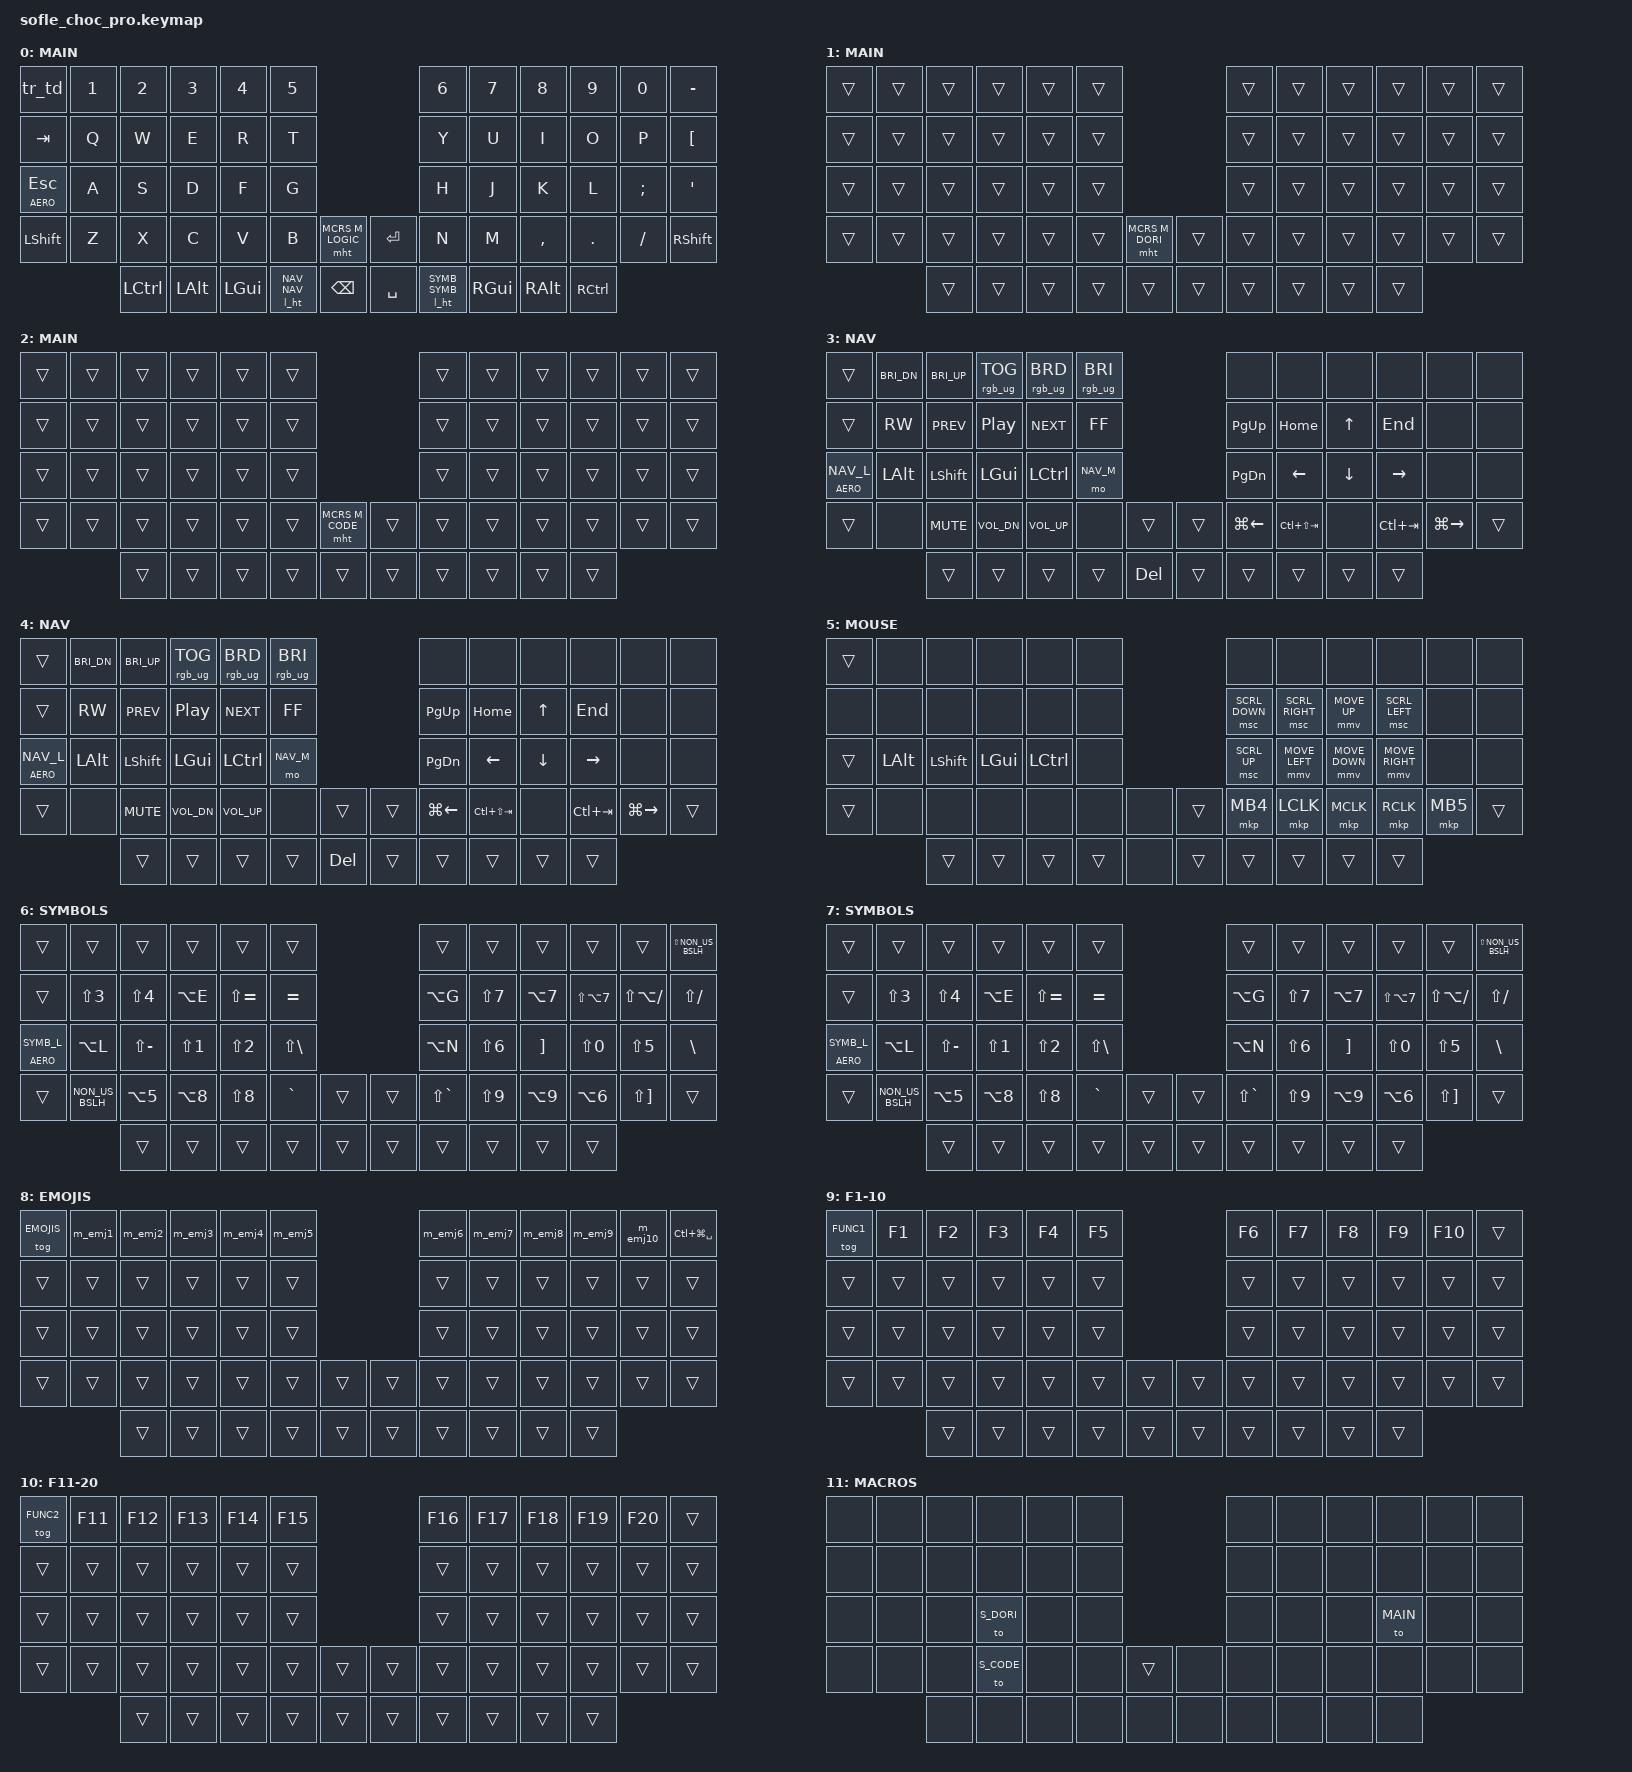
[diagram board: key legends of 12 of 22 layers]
/*
* Copyright (c) 2020 The ZMK Contributors
*
* SPDX-License-Identifier: MIT
*/

#include <behaviors.dtsi>
#include <dt-bindings/zmk/keys.h>
#include <dt-bindings/zmk/pointing.h>
#include <dt-bindings/zmk/bt.h>
#include <dt-bindings/zmk/rgb.h>
#include <dt-bindings/zmk/ext_power.h>

#define MAIN      0
#define S_DORI    1
#define S_CODE    2
#define NAV       3
#define NAV_L     4
#define NAV_M     5
#define SYMB      6
#define SYMB_L    7
#define EMOJIS    8
#define FUNC1     9
#define FUNC2     10
#define MCRS      11
#define M_LOGIC   12
#define M_LOGIC_L 13
#define M_DORI    14
#define M_DORI_L  15
#define M_CODE    16
#define M_CODE_L  17
#define AERO      18
#define AERO_L    19
#define AERO_R    20
#define SERV      21

#include "macros.dtsi"
#include "custom_behaviors.dtsi"

/ {
     // Activate SERVICE layer by pressing both NAV and SYMB
     conditional_layers {
          compatible = "zmk,conditional-layers";
          adjust_layer {
               if-layers = <NAV SYMB>;
               then-layer = <SERV>;
          };
     };

     keymap {
          compatible = "zmk,keymap";

          main_layer {
               display-name = "MAIN";
               bindings = <
               // ┌──────────────┬──────────────┬──────────────┬──────────────┬──────────────┬──────────────┐                              ┌──────────────┬──────────────┬──────────────┬──────────────┬──────────────┬──────────────┐
               // │ TR TAP DANCE │ 1            │ 2            │ 3            │ 4            │ 5            │                              │ 6            │ 7            │ 8            │ 9            │ 0            │ ß            │
                    &tr_td         &kp N1         &kp N2         &kp N3         &kp N4         &kp N5                                        &kp N6         &kp N7         &kp N8         &kp N9         &kp N0         &kp MINUS
               // ├──────────────┼──────────────┼──────────────┼──────────────┼──────────────┼──────────────┤                              ├──────────────┼──────────────┼──────────────┼──────────────┼──────────────┼──────────────┤
               // │ TAB          │ Q            │ W            │ E            │ R            │ T            │                              │ Z            │ U            │ I            │ O            │ P            │ Ü            │
                    &kp TAB        &kp Q          &kp W          &kp E          &kp R          &kp T                                         &kp Y          &kp U          &kp I          &kp O          &kp P          &kp LBKT
               // ├──────────────┼──────────────┼──────────────┼──────────────┼──────────────┼──────────────┤                              ├──────────────┼──────────────┼──────────────┼──────────────┼──────────────┼──────────────┤
               // │ ESC / AERO   │ A            │ S            │ D            │ F            │ G            │                              │ H            │ J            │ K            │ L            │ Ö            │ Ä            │
                    &as_t AERO ESC &kp A          &kp S          &kp D          &kp F          &kp G                                         &kp H          &kp J          &kp K          &kp L          &kp SEMI       &kp SQT
               // ├──────────────┼──────────────┼──────────────┼──────────────┼──────────────┼──────────────┼──────────────┐┌──────────────┼──────────────┼──────────────┼──────────────┼──────────────┼──────────────┼──────────────┤
               // │ SHIFT Left   │ Y            │ X            │ C            │ V            │ B            │ MACROS       ││ ENTER        │ N            │ M            │ ,            │ .            │ -            │ SHIFT Right  │
                    &kp LSHFT      &kp Z          &kp X          &kp C          &kp V          &kp B          &mht MCRS M_LOGIC &kp RET      &kp N          &kp M          &kp COMMA      &kp DOT        &kp FSLH       &kp RSHFT
               // └──────────────┴──────────────┼──────────────┼──────────────┼──────────────┼──────────────┼──────────────┤├──────────────┼──────────────┼──────────────┼──────────────┼──────────────┼──────────────┴──────────────┘
               //                               │ CTRL Left    │ OPT Left     │ CMD Left     │ NAV          │ BACKSPACE    ││ SPACE        │ SYMBOLS      │ CMD Right    │ OPT Right    │ CTRL Right   │
                                                  &kp LCTRL      &kp LALT       &kp LGUI       &l_ht NAV NAV  &kp BSPC        &kp SPACE      &l_ht SYMB SYMB  &kp RGUI     &kp RALT       &kp RCTRL
               //                               └──────────────┴──────────────┴──────────────┴──────────────┴──────────────┘└──────────────┴──────────────┴──────────────┴──────────────┴──────────────┘
               >;
          };

          macro_overlay_dorico_layer {
               display-name = "MAIN";
               bindings = <
                  &trans &trans &trans &trans &trans &trans                         &trans &trans &trans &trans &trans &trans
                  &trans &trans &trans &trans &trans &trans                         &trans &trans &trans &trans &trans &trans
                  &trans &trans &trans &trans &trans &trans                         &trans &trans &trans &trans &trans &trans
                  &trans &trans &trans &trans &trans &trans &mht MCRS M_DORI &trans &trans &trans &trans &trans &trans &trans
                                &trans &trans &trans &trans &trans           &trans &trans &trans &trans &trans
               >;
          };

          macro_overlay_coding_layer {
               display-name = "MAIN";
               bindings = <
                  &trans &trans &trans &trans &trans &trans                         &trans &trans &trans &trans &trans &trans
                  &trans &trans &trans &trans &trans &trans                         &trans &trans &trans &trans &trans &trans
                  &trans &trans &trans &trans &trans &trans                         &trans &trans &trans &trans &trans &trans
                  &trans &trans &trans &trans &trans &trans &mht MCRS M_CODE &trans &trans &trans &trans &trans &trans &trans
                                &trans &trans &trans &trans &trans           &trans &trans &trans &trans &trans
               >;
          };

          nav_layer {
               display-name = "NAV";
               bindings = <
               // ┌──────────────┬──────────────┬──────────────┬──────────────┬──────────────┬──────────────┐                              ┌──────────────┬──────────────┬──────────────┬──────────────┬──────────────┬──────────────┐
               // │              │ BRIGHTN DOWN │ BRIGHTN UP   │KB LI TOGGLE    KB LI DOWN   │ KB LI UP     │                              │              │              │              │              │              │              │
                    &trans         &kp C_BRI_DN   &kp C_BRI_UP  &rgb_ug RGB_TOG &rgb_ug RGB_BRD &rgb_ug RGB_BRI                              &none          &none          &none          &none          &none          &none
               // ├──────────────┼──────────────┼──────────────┼──────────────┼──────────────┼──────────────┤                              ├──────────────┼──────────────┼──────────────┼──────────────┼──────────────┼──────────────┤
               // │              │ REWIND       │ PREVIOUS     │ PLAY/PAUSE   │ NEXT         │ FAST FWD     │                              │ Page Up      │ Home         │ ↑            │ End          │              │              │
                    &trans         &kp C_RW       &kp C_PREV     &kp C_PP       &kp C_NEXT     &kp C_FF                                      &kp PG_UP      &kp HOME       &kp UP         &kp END        &none          &none
               // ├──────────────┼──────────────┼──────────────┼──────────────┼──────────────┼──────────────┤                              ├──────────────┼──────────────┼──────────────┼──────────────┼──────────────┼──────────────┤
               // │ LOCK/AERO    │ OPT Left     │ SHIFT Left   │ CMD Left     │ CTRL Left    │ MOUSE CTRL   │                              │ Page Down    │ ←            │ ↓            │ →            │              │              │
                    &as_l AERO NAV_L &kp LALT     &kp LSHFT      &kp LGUI       &kp LCTRL      &mo NAV_M                                     &kp PG_DN      &kp LEFT       &kp DOWN       &kp RIGHT      &none          &none
               // ├──────────────┼──────────────┼──────────────┼──────────────┼──────────────┼──────────────┼──────────────┐┌──────────────┼──────────────┼──────────────┼──────────────┼──────────────┼──────────────┼──────────────┤
               // │              │              │ MUTE         │ VOL DOWN     │ VOL UP       │              │              ││              │ Prev         │ Prev Tab     │              │ Next Tab     │ Next         │              │
                    &trans         &none          &kp C_MUTE     &kp C_VOL_DN   &kp C_VOL_UP   &none          &trans          &trans         &kp LG(LEFT)   &kp LC(LS(TAB)) &none         &kp LC(TAB)    &kp LG(RIGHT)  &trans
               // └──────────────┴──────────────┼──────────────┼──────────────┼──────────────┼──────────────┼──────────────┤├──────────────┼──────────────┼──────────────┼──────────────┼──────────────┼──────────────┴──────────────┘
               //                               │              │              │              │ (HELD)       │ DELETE       ││              │              │              │              │              │
                                                  &trans         &trans         &trans         &trans         &kp DEL         &trans         &trans         &trans         &trans         &trans
               //                               └──────────────┴──────────────┴──────────────┴──────────────┴──────────────┘└──────────────┴──────────────┴──────────────┴──────────────┴──────────────┘
               >;
          };

          nav_locked_layer {
               display-name = "NAV";
               bindings = <
               // ┌──────────────┬──────────────┬──────────────┬──────────────┬──────────────┬──────────────┐                              ┌──────────────┬──────────────┬──────────────┬──────────────┬──────────────┬──────────────┐
               // │              │ BRIGHTN DOWN │ BRIGHTN UP   │KB LI TOGGLE    KB LI DOWN   │ KB LI UP     │                              │              │              │              │              │              │              │
                    &trans         &kp C_BRI_DN   &kp C_BRI_UP  &rgb_ug RGB_TOG &rgb_ug RGB_BRD &rgb_ug RGB_BRI                              &none          &none          &none          &none          &none          &none
               // ├──────────────┼──────────────┼──────────────┼──────────────┼──────────────┼──────────────┤                              ├──────────────┼──────────────┼──────────────┼──────────────┼──────────────┼──────────────┤
               // │              │ REWIND       │ PREVIOUS     │ PLAY/PAUSE   │ NEXT         │ FAST FWD     │                              │ Page Up      │ Home         │ ↑            │ End          │              │              │
                    &trans         &kp C_RW       &kp C_PREV     &kp C_PP       &kp C_NEXT     &kp C_FF                                      &kp PG_UP      &kp HOME       &kp UP         &kp END        &none          &none
               // ├──────────────┼──────────────┼──────────────┼──────────────┼──────────────┼──────────────┤                              ├──────────────┼──────────────┼──────────────┼──────────────┼──────────────┼──────────────┤
               // │ UNLOCK/AERO  │ OPT Left     │ SHIFT Left   │ CMD Left     │ CTRL Left    │ MOUSE CTRL   │                              │ Page Down    │ ←            │ ↓            │ →            │              │              │
                    &as_l AERO NAV_L &kp LALT     &kp LSHFT      &kp LGUI       &kp LCTRL      &mo NAV_M                                     &kp PG_DN      &kp LEFT       &kp DOWN       &kp RIGHT      &none          &none
               // ├──────────────┼──────────────┼──────────────┼──────────────┼──────────────┼──────────────┼──────────────┐┌──────────────┼──────────────┼──────────────┼──────────────┼──────────────┼──────────────┼──────────────┤
               // │              │              │ MUTE         │ VOL DOWN     │ VOL UP       │              │              ││              │ Prev         │ Prev Tab     │              │ Next Tab     │ Next         │              │
                    &trans         &none          &kp C_MUTE     &kp C_VOL_DN   &kp C_VOL_UP   &none          &trans          &trans         &kp LG(LEFT)   &kp LC(LS(TAB)) &none         &kp LC(TAB)    &kp LG(RIGHT)  &trans
               // └──────────────┴──────────────┼──────────────┼──────────────┼──────────────┼──────────────┼──────────────┤├──────────────┼──────────────┼──────────────┼──────────────┼──────────────┼──────────────┴──────────────┘
               //                               │              │              │              │ (HELD)       │ DELETE       ││              │              │              │              │              │
                                                  &trans         &trans         &trans         &trans         &kp DEL         &trans         &trans         &trans         &trans         &trans
               //                               └──────────────┴──────────────┴──────────────┴──────────────┴──────────────┘└──────────────┴──────────────┴──────────────┴──────────────┴──────────────┘
               >;
          };

          nav_mouse_layer {
               display-name = "MOUSE";
               bindings = <
               // ┌──────────────┬──────────────┬──────────────┬──────────────┬──────────────┬──────────────┐                              ┌──────────────┬──────────────┬──────────────┬──────────────┬──────────────┬──────────────┐
               // │              │              │              │              │              │              │                              │              │              │              │              │              │              │
                    &trans         &none          &none          &none          &none          &none                                         &none          &none          &none          &none          &none          &none
               // ├──────────────┼──────────────┼──────────────┼──────────────┼──────────────┼──────────────┤                              ├──────────────┼──────────────┼──────────────┼──────────────┼──────────────┼──────────────┤
               // │              │              │              │              │              │              │                              │ ↑ SCROLL     │ ← SCROLL     │ ↑ MOVE       │ → SCROLL     │              │              │
                    &none          &none          &none          &none          &none          &none                                         &msc SCRL_DOWN &msc SCRL_RIGHT &mmv MOVE_UP   &msc SCRL_LEFT       &none   &none
               // ├──────────────┼──────────────┼──────────────┼──────────────┼──────────────┼──────────────┤                              ├──────────────┼──────────────┼──────────────┼──────────────┼──────────────┼──────────────┤
               // │              │ OPT Left     │ SHIFT Left   │ CMD Left     │ CTRL Left    │ (HELD)       │                              │ ↓ SCROLL     │ ← MOVE       │ ↓ MOVE       │ → MOVE       │              │              │
                    &trans         &kp LALT       &kp LSHFT      &kp LGUI       &kp LCTRL      &none                                         &msc SCRL_UP   &mmv MOVE_LEFT &mmv MOVE_DOWN &mmv MOVE_RIGHT       &none   &none
               // ├──────────────┼──────────────┼──────────────┼──────────────┼──────────────┼──────────────┼──────────────┐┌──────────────┼──────────────┼──────────────┼──────────────┼──────────────┼──────────────┼──────────────┤
               // │              │              │              │              │              │              │              ││              │ MB4 (BACK)   │ LEFT CLICK   │ MIDDLE CLICK │ RIGHT CLICK  │ MB5 (FWD)    │              │
                    &trans         &none          &none          &none          &none          &none          &none           &trans         &mkp MB4       &mkp LCLK      &mkp MCLK      &mkp RCLK      &mkp MB5       &trans
               // └──────────────┴──────────────┼──────────────┼──────────────┼──────────────┼──────────────┼──────────────┤├──────────────┼──────────────┼──────────────┼──────────────┼──────────────┼──────────────┴──────────────┘
               //                               │              │              │              │ (HELD)       │              ││              │              │              │              │              │
                                                  &trans         &trans         &trans         &trans         &none           &trans         &trans         &trans         &trans         &trans
               //                               └──────────────┴──────────────┴──────────────┴──────────────┴──────────────┘└──────────────┴──────────────┴──────────────┴──────────────┴──────────────┘
               >;
          };

          symbol_layer {
               display-name = "SYMBOLS";
               bindings = <
               // ┌──────────────┬──────────────┬──────────────┬──────────────┬──────────────┬──────────────┐                              ┌──────────────┬──────────────┬──────────────┬──────────────┬──────────────┬──────────────┐
               // │              │              │              │              │              │              │                              │              │              │              │              │              │ °            │
                    &trans         &trans         &trans         &trans         &trans         &trans                                        &trans         &trans         &trans         &trans         &trans         &kp LS(NON_US_BSLH)
               // ├──────────────┼──────────────┼──────────────┼──────────────┼──────────────┼──────────────┤                              ├──────────────┼──────────────┼──────────────┼──────────────┼──────────────┼──────────────┤
               // │              │ §            │ $            │ €            │ `            │ ´            │                              │ ©            │ /            │ |            │ \            │ —            │ _            │
                    &trans         &kp LS(N3)     &kp LS(N4)     &kp LA(E)      &kp LS(EQUAL)  &kp EQUAL                                     &kp LA(G)      &kp LS(N7)     &kp LA(N7)     &kp LS(LA(N7)) &kp LS(LA(FSLH)) &kp LS(FSLH)
               // ├──────────────┼──────────────┼──────────────┼──────────────┼──────────────┼──────────────┤                              ├──────────────┼──────────────┼──────────────┼──────────────┼──────────────┼──────────────┤
               // │ LOCK/AERO    │ @            │ ?            │ !            │ "            │ '            │                              │ ~            │ &            │ +            │ =            │ %            │ #            │
                    &as_l AERO SYMB_L &kp LA(L)   &kp LS(MINUS)  &kp LS(N1)     &kp LS(N2)     &kp LS(BSLH)                                  &kp LA(N)      &kp LS(N6)     &kp RBKT       &kp LS(N0)     &kp LS(N5)     &kp BSLH
               // ├──────────────┼──────────────┼──────────────┼──────────────┼──────────────┼──────────────┼──────────────┐┌──────────────┼──────────────┼──────────────┼──────────────┼──────────────┼──────────────┼──────────────┤
               // │              │ ^            │ [            │ {            │ (            │ <            │              ││              │ >            │ )            │ }            │ ]            │ *            │              │
                    &trans         &kp NON_US_BSLH &kp LA(N5)    &kp LA(N8)     &kp LS(N8)     &kp GRAVE      &trans          &trans         &kp LS(GRAVE)   &kp LS(N9)     &kp LA(N9)     &kp LA(N6)     &kp LS(RBKT)   &trans
               // └──────────────┴──────────────┼──────────────┼──────────────┼──────────────┼──────────────┼──────────────┤├──────────────┼──────────────┼──────────────┼──────────────┼──────────────┼──────────────┴──────────────┘
               //                               │              │              │              │              │              ││              │ (HELD)       │              │              │              │
                                                  &trans         &trans         &trans         &trans         &trans          &trans         &trans         &trans         &trans         &trans
               //                               └──────────────┴──────────────┴──────────────┴──────────────┴──────────────┘└──────────────┴──────────────┴──────────────┴──────────────┴──────────────┘
               >;
          };

          symbol_locked_layer {
               display-name = "SYMBOLS";
               bindings = <
               // ┌──────────────┬──────────────┬──────────────┬──────────────┬──────────────┬──────────────┐                              ┌──────────────┬──────────────┬──────────────┬──────────────┬──────────────┬──────────────┐
               // │              │              │              │              │              │              │                              │              │              │              │              │              │ °            │
                    &trans         &trans         &trans         &trans         &trans         &trans                                        &trans         &trans         &trans         &trans         &trans         &kp LS(NON_US_BSLH)
               // ├──────────────┼──────────────┼──────────────┼──────────────┼──────────────┼──────────────┤                              ├──────────────┼──────────────┼──────────────┼──────────────┼──────────────┼──────────────┤
               // │              │ §            │ $            │ €            │ `            │ ´            │                              │ ©            │ /            │ |            │ \            │ —            │ _            │
                    &trans         &kp LS(N3)     &kp LS(N4)     &kp LA(E)      &kp LS(EQUAL)  &kp EQUAL                                     &kp LA(G)      &kp LS(N7)     &kp LA(N7)     &kp LS(LA(N7)) &kp LS(LA(FSLH)) &kp LS(FSLH)
               // ├──────────────┼──────────────┼──────────────┼──────────────┼──────────────┼──────────────┤                              ├──────────────┼──────────────┼──────────────┼──────────────┼──────────────┼──────────────┤
               // │ UNLOCK/AERO  │ @            │ ?            │ !            │ "            │ '            │                              │ ~            │ &            │ +            │ =            │ %            │ #            │
                    &as_l AERO SYMB_L &kp LA(L)   &kp LS(MINUS)  &kp LS(N1)     &kp LS(N2)     &kp LS(BSLH)                                  &kp LA(N)      &kp LS(N6)     &kp RBKT       &kp LS(N0)     &kp LS(N5)     &kp BSLH
               // ├──────────────┼──────────────┼──────────────┼──────────────┼──────────────┼──────────────┼──────────────┐┌──────────────┼──────────────┼──────────────┼──────────────┼──────────────┼──────────────┼──────────────┤
               // │              │ ^            │ [            │ {            │ (            │ <            │              ││              │ >            │ )            │ }            │ ]            │ *            │              │
                    &trans         &kp NON_US_BSLH &kp LA(N5)    &kp LA(N8)     &kp LS(N8)     &kp GRAVE      &trans          &trans         &kp LS(GRAVE)   &kp LS(N9)     &kp LA(N9)     &kp LA(N6)     &kp LS(RBKT)   &trans
               // └──────────────┴──────────────┼──────────────┼──────────────┼──────────────┼──────────────┼──────────────┤├──────────────┼──────────────┼──────────────┼──────────────┼──────────────┼──────────────┴──────────────┘
               //                               │              │              │              │              │              ││              │ (HELD)       │              │              │              │
                                                  &trans         &trans         &trans         &trans         &trans          &trans         &trans         &trans         &trans         &trans
               //                               └──────────────┴──────────────┴──────────────┴──────────────┴──────────────┘└──────────────┴──────────────┴──────────────┴──────────────┴──────────────┘
               >;
          };

          emoji_layer {
               display-name = "EMOJIS";
               bindings = <
               // ┌──────────────┬──────────────┬──────────────┬──────────────┬──────────────┬──────────────┐                              ┌──────────────┬──────────────┬──────────────┬──────────────┬──────────────┬──────────────┐
               // │ Exit Emojis  │ 😊           │ 🤗            │ 😂           │ 😅           │ 🥲            │                              │ ❤️           │ 😍           │ 👍🏻            │ 🙈           │ 🤔           │ More Emojis  │
                    &tog EMOJIS    &m_emj1        &m_emj2        &m_emj3        &m_emj4        &m_emj5                                       &m_emj6        &m_emj7        &m_emj8        &m_emj9        &m_emj10       &kp LC(LG(SPACE))
               // ├──────────────┼──────────────┼──────────────┼──────────────┼──────────────┼──────────────┤                              ├──────────────┼──────────────┼──────────────┼──────────────┼──────────────┼──────────────┤
                    &trans         &trans         &trans         &trans         &trans         &trans                                        &trans         &trans         &trans         &trans         &trans         &trans
                    &trans         &trans         &trans         &trans         &trans         &trans                                        &trans         &trans         &trans         &trans         &trans         &trans
                    &trans         &trans         &trans         &trans         &trans         &trans         &trans          &trans         &trans         &trans         &trans         &trans         &trans         &trans
                                                  &trans         &trans         &trans         &trans         &trans          &trans         &trans         &trans         &trans         &trans
               >;
          };

          function1_layer {
               display-name = "F1-10";
               bindings = <
               // ┌──────────────┬──────────────┬──────────────┬──────────────┬──────────────┬──────────────┐                              ┌──────────────┬──────────────┬──────────────┬──────────────┬──────────────┬──────────────┐
               // │ Exit FUNC1   │ F1           │ F2           │ F3           │ F4           │ F5           │                              │ F6           │ F7           │ F8           │ F9           │ F10          │              │
                    &tog FUNC1     &kp F1         &kp F2         &kp F3         &kp F4         &kp F5                                        &kp F6         &kp F7         &kp F8         &kp F9         &kp F10        &trans
               // ├──────────────┼──────────────┼──────────────┼──────────────┼──────────────┼──────────────┤                              ├──────────────┼──────────────┼──────────────┼──────────────┼──────────────┼──────────────┤
                    &trans         &trans         &trans         &trans         &trans         &trans                                        &trans         &trans         &trans         &trans         &trans         &trans
                    &trans         &trans         &trans         &trans         &trans         &trans                                        &trans         &trans         &trans         &trans         &trans         &trans
                    &trans         &trans         &trans         &trans         &trans         &trans         &trans          &trans         &trans         &trans         &trans         &trans         &trans         &trans
                                                  &trans         &trans         &trans         &trans         &trans          &trans         &trans         &trans         &trans         &trans
               >;
          };

          function2_layer {
               display-name = "F11-20";
               bindings = <
               // ┌──────────────┬──────────────┬──────────────┬──────────────┬──────────────┬──────────────┐                              ┌──────────────┬──────────────┬──────────────┬──────────────┬──────────────┬──────────────┐
               // │ Exit FUNC2   │ F11          │ F12          │ F13          │ F14          │ F15          │                              │ F16          │ F17          │ F18          │ F19          │ F20          │              │
                    &tog FUNC2     &kp F11        &kp F12        &kp F13        &kp F14        &kp F15                                       &kp F16        &kp F17        &kp F18        &kp F19        &kp F20        &trans
               // ├──────────────┼──────────────┼──────────────┼──────────────┼──────────────┼──────────────┤                              ├──────────────┼──────────────┼──────────────┼──────────────┼──────────────┼──────────────┤
                    &trans         &trans         &trans         &trans         &trans         &trans                                        &trans         &trans         &trans         &trans         &trans         &trans
                    &trans         &trans         &trans         &trans         &trans         &trans                                        &trans         &trans         &trans         &trans         &trans         &trans
                    &trans         &trans         &trans         &trans         &trans         &trans         &trans          &trans         &trans         &trans         &trans         &trans         &trans         &trans
                                                  &trans         &trans         &trans         &trans         &trans          &trans         &trans         &trans         &trans         &trans
               >;
          };

          macros_select_layer {
               display-name = "MACROS";
               bindings = <
               // ┌──────────────┬──────────────┬──────────────┬──────────────┬──────────────┬──────────────┐                              ┌──────────────┬──────────────┬──────────────┬──────────────┬──────────────┬──────────────┐
               // │              │              │              │              │              │              │                              │              │              │              │              │              │              │
                    &none          &none          &none          &none          &none          &none                                         &none          &none          &none          &none          &none          &none
               // ├──────────────┼──────────────┼──────────────┼──────────────┼──────────────┼──────────────┤                              ├──────────────┼──────────────┼──────────────┼──────────────┼──────────────┼──────────────┤
               // │              │              │              │              │              │              │                              │              │              │              │              │              │              │
                    &none          &none          &none          &none          &none          &none                                         &none          &none          &none          &none          &none          &none
               // ├──────────────┼──────────────┼──────────────┼──────────────┼──────────────┼──────────────┤                              ├──────────────┼──────────────┼──────────────┼──────────────┼──────────────┼──────────────┤
               // │              │              │              │ DORICO       │              │              │                              │              │              │              │ LOGIC        │              │              │
                    &none          &none          &none          &to S_DORI     &none          &none                                         &none          &none          &none          &to MAIN       &none          &none
               // ├──────────────┼──────────────┼──────────────┼──────────────┼──────────────┼──────────────┼──────────────┐┌──────────────┼──────────────┼──────────────┼──────────────┼──────────────┼──────────────┼──────────────┤
               // │              │              │              │ CODING       │              │              │ (Held)       ││              │              │              │              │              │              │              │
                    &none          &none          &none          &to S_CODE     &none          &none          &trans          &none          &none          &none          &none          &none          &none          &none
               // └──────────────┴──────────────┼──────────────┼──────────────┼──────────────┼──────────────┼──────────────┤├──────────────┼──────────────┼──────────────┼──────────────┼──────────────┼──────────────┴──────────────┘
               //                               │              │              │              │              │              ││              │              │              │              │              │
                                                  &none          &none          &none          &none          &none           &none          &none          &none          &none          &none
               //                               └──────────────┴──────────────┴──────────────┴──────────────┴──────────────┘└──────────────┴──────────────┴──────────────┴──────────────┴──────────────┘
               >;
          };

          macros_logic_layer {
               display-name = "LOGIC";
               bindings = <
               // ┌──────────────┬──────────────┬──────────────┬──────────────┬──────────────┬──────────────┐                              ┌──────────────┬──────────────┬──────────────┬──────────────┬──────────────┬──────────────┐
               // │              │              │              │              │              │              │                              │              │              │              │              │              │              │
                    &none          &none          &none          &none          &none          &none                                         &none          &none          &none          &none          &none          &none
               // ├──────────────┼──────────────┼──────────────┼──────────────┼──────────────┼──────────────┤                              ├──────────────┼──────────────┼──────────────┼──────────────┼──────────────┼──────────────┤
               // │              │              │ MOVE ←       │ MOVE →       │ MV->REC-POS  │ MV->PLAYHEAD │                              │              │ JUMP REGION ←│              │ JUMP REGION →│              │              │
                    &none          &none          &kp LA(LEFT)   &kp LA(RIGHT)  &kp LS(LA(LG(R))) &kp LG(BSLH)                               &none          &kp LS(LA(LG(LEFT)))  &none   &kp LS(LA(LG(RIGHT))) &none   &none
               // ├──────────────┼──────────────┼──────────────┼──────────────┼──────────────┼──────────────┤                              ├──────────────┼──────────────┼──────────────┼──────────────┼──────────────┼──────────────┤
               // │ LOCK/AERO    │ POINTER      │ SCISSORS     │ PENCIL/DRAW  │ FADE         │ GAIN         │                              │              │ SET IN-PT    │ SET IN-OUT   │ SET OUT-PT   │              │              │
                    &as_l AERO M_LOGIC_L &kp LS(LA(LG(P))) &kp LS(LA(LG(S))) &kp LS(LA(LG(LBKT))) &kp LS(LA(LG(F))) &kp LS(LA(LG(G)))        &none          &kp LC(LG(X))  &kp LG(U)      &kp LS(LA(LC(L)))     &none   &none
               // ├──────────────┼──────────────┼──────────────┼──────────────┼──────────────┼──────────────┼──────────────┐┌──────────────┼──────────────┼──────────────┼──────────────┼──────────────┼──────────────┼──────────────┤
               // │              │              │              │              │              │              │              ││              │              │              │              │              │              │              │
                    &none          &none          &none          &none          &none          &none          &none           &none          &none          &none          &none          &none          &none          &none
               // └──────────────┴──────────────┼──────────────┼──────────────┼──────────────┼──────────────┼──────────────┤├──────────────┼──────────────┼──────────────┼──────────────┼──────────────┼──────────────┴──────────────┘
               //                               │              │              │              │              │              ││              │              │              │              │              │
                                                  &none          &none          &none          &to MAIN       &none           &none          &to MAIN       &none          &none          &none
               //                               └──────────────┴──────────────┴──────────────┴──────────────┴──────────────┘└──────────────┴──────────────┴──────────────┴──────────────┴──────────────┘
               >;
          };

          macros_logic_locked_layer {
               display-name = "LOGIC";
               bindings = <
               // ┌──────────────┬──────────────┬──────────────┬──────────────┬──────────────┬──────────────┐                              ┌──────────────┬──────────────┬──────────────┬──────────────┬──────────────┬──────────────┐
               // │              │              │              │              │              │              │                              │              │              │              │              │              │              │
                    &none          &none          &none          &none          &none          &none                                         &none          &none          &none          &none          &none          &none
               // ├──────────────┼──────────────┼──────────────┼──────────────┼──────────────┼──────────────┤                              ├──────────────┼──────────────┼──────────────┼──────────────┼──────────────┼──────────────┤
               // │              │              │ MOVE ←       │ MOVE →       │ MV->REC-POS  │ MV->PLAYHEAD │                              │              │ JUMP REGION ←│              │ JUMP REGION →│              │              │
                    &none          &none          &kp LA(LEFT)   &kp LA(RIGHT)  &kp LS(LA(LG(R))) &kp LG(BSLH)                               &none          &kp LS(LA(LG(LEFT)))  &none   &kp LS(LA(LG(RIGHT))) &none   &none
               // ├──────────────┼──────────────┼──────────────┼──────────────┼──────────────┼──────────────┤                              ├──────────────┼──────────────┼──────────────┼──────────────┼──────────────┼──────────────┤
               // │ UNLOCK/AERO  │ POINTER      │ SCISSORS     │ PENCIL/DRAW  │ FADE         │ GAIN         │                              │              │ SET IN-PT    │ SET IN-OUT   │ SET OUT-PT   │              │              │
                    &as_l AERO M_LOGIC_L &kp LS(LA(LG(P))) &kp LS(LA(LG(S))) &kp LS(LA(LG(LBKT))) &kp LS(LA(LG(F))) &kp LS(LA(LG(G)))        &none          &kp LC(LG(X))  &kp LG(U)      &kp LS(LA(LC(L)))     &none   &none
               // ├──────────────┼──────────────┼──────────────┼──────────────┼──────────────┼──────────────┼──────────────┐┌──────────────┼──────────────┼──────────────┼──────────────┼──────────────┼──────────────┼──────────────┤
               // │              │              │              │              │              │              │              ││              │              │              │              │              │              │              │
                    &none          &none          &none          &none          &none          &none          &none           &none          &none          &none          &none          &none          &none          &none
               // └──────────────┴──────────────┼──────────────┼──────────────┼──────────────┼──────────────┼──────────────┤├──────────────┼──────────────┼──────────────┼──────────────┼──────────────┼──────────────┴──────────────┘
               //                               │              │              │              │              │              ││              │              │              │              │              │
                                                  &none          &none          &none          &to MAIN       &none           &none          &to MAIN       &none          &none          &none
               //                               └──────────────┴──────────────┴──────────────┴──────────────┴──────────────┘└──────────────┴──────────────┴──────────────┴──────────────┴──────────────┘
               >;
          };

          macros_dorico_layer {
               display-name = "DORICO";
               bindings = <
               // ┌──────────────┬──────────────┬──────────────┬──────────────┬──────────────┬──────────────┐                              ┌──────────────┬──────────────┬──────────────┬──────────────┬──────────────┬──────────────┐
               // │              │ Filt Select  │ Filt Desel.  │ Filt Lyrics  │ Filt Techni. │ Filt Dyn.    │                              │ Filt Top N.  │ Filt Bot N.  │ Filt Slurs   │ Filt Rests   │ Filt Tupl.   │ Filt Gliss.  │
                    &none          &kp LC(LA(S))  &kp LC(LA(LG(S))) &kp LC(LG(L)) &kp LC(LG(P)) &kp LS(LC(LG(D)))                            &kp LC(LG(UP)) &kp LC(LG(DOWN)) &kp LC(LG(S)) &kp LC(LG(R)) &kp LC(LG(N))  &kp LS(LA(LG(G)))
               // ├──────────────┼──────────────┼──────────────┼──────────────┼──────────────┼──────────────┤                              ├──────────────┼──────────────┼──────────────┼──────────────┼──────────────┼──────────────┤
               // │              │              │ Prev Layout  │ Next Layout  │ Rem Trem.    │ Add Tremolo  │                              │ Def. N.head  │ Decr Dyn Int │ Move/Cpy Up  │ Incr Dyn Int │ Page View    │ Res. Beaming │
                    &none          &none     &kp LC(LA(LG(UP))) &kp LC(LA(LG(DOWN))) &kp LS(LA(LG(T))) &kp LA(LG(T))                         &kp LC(LA(LG(X))) &kp LC(LA(LG(U))) &dori_up &kp LC(LA(LG(O))) &kp LA(LG(N1)) &kp LC(LA(B))
               // ├──────────────┼──────────────┼──────────────┼──────────────┼──────────────┼──────────────┤                              ├──────────────┼──────────────┼──────────────┼──────────────┼──────────────┼──────────────┤
               // │ LOCK/AERO    │ Align Dyn.   │ Unison       │ Divisi       │ Filt Notes   │              │                              │ X Notehead   │ Decr Grid    │ Move/Cpy Dwn │ Incr Grid    │ Galley View  │ Res. Stems   │
                    &as_l AERO M_DORI_L &kp LS(LA(LG(A))) &kp LS(LC(D)) &kp LS(LG(D)) &kp LC(LA(LG(N))) &none                                &kp LS(LA(LG(X))) &kp LC(LA(LG(LEFT))) &dori_dn &kp LC(LA(LG(RIGHT))) &kp LA(LG(N2)) &kp LS(LA(LG(S)))
               // ├──────────────┼──────────────┼──────────────┼──────────────┼──────────────┼──────────────┼──────────────┐┌──────────────┼──────────────┼──────────────┼──────────────┼──────────────┼──────────────┼──────────────┤
               // │ SHIFT LEFT   │ Rem.Dyn.f.G. │ Ungroup Dyn. │ Group Dyn.   │ Filt&Rm Dyn. │ Dbl. Barline │              ││              │              │              │ Select More  │              │              │              │
                    &kp LSHFT      &kp LC(LG(G))  &kp LC(LA(LG(G))) &kp LC(LA(G)) &m_d_frd     &m_d_dbar      &none           &none          &none          &none          &kp LS(LG(A))  &none          &none          &none
               // └──────────────┴──────────────┼──────────────┼──────────────┼──────────────┼──────────────┼──────────────┤├──────────────┼──────────────┼──────────────┼──────────────┼──────────────┼──────────────┴──────────────┘
               //                               │              │              │              │              │              ││              │              │              │              │              │
                                                  &none          &none          &none          &to S_DORI     &none           &none          &to S_DORI     &none          &none          &none
               //                               └──────────────┴──────────────┴──────────────┴──────────────┴──────────────┘└──────────────┴──────────────┴──────────────┴──────────────┴──────────────┘
               >;
          };

          macros_dorico_locked_layer {
               display-name = "DORICO";
               bindings = <
               // ┌──────────────┬──────────────┬──────────────┬──────────────┬──────────────┬──────────────┐                              ┌──────────────┬──────────────┬──────────────┬──────────────┬──────────────┬──────────────┐
               // │              │ Filt Select  │ Filt Desel.  │ Filt Lyrics  │ Filt Techni. │ Filt Dyn.    │                              │ Filt Top N.  │ Filt Bot N.  │ Filt Slurs   │ Filt Rests   │ Filt Tupl.   │ Filt Gliss.  │
                    &none          &kp LC(LA(S))  &kp LC(LA(LG(S))) &kp LC(LG(L)) &kp LC(LG(P)) &kp LS(LC(LG(D)))                            &kp LC(LG(UP)) &kp LC(LG(DOWN)) &kp LC(LG(S)) &kp LC(LG(R)) &kp LC(LG(N))  &kp LS(LA(LG(G)))
               // ├──────────────┼──────────────┼──────────────┼──────────────┼──────────────┼──────────────┤                              ├──────────────┼──────────────┼──────────────┼──────────────┼──────────────┼──────────────┤
               // │              │              │ Prev Layout  │ Next Layout  │ Rem Trem.    │ Add Tremolo  │                              │ Def. N.head  │ Decr Dyn Int │ Move/Cpy Up  │ Incr Dyn Int │ Page View    │ Res. Beaming │
                    &none          &none     &kp LC(LA(LG(UP))) &kp LC(LA(LG(DOWN))) &kp LS(LA(LG(T))) &kp LA(LG(T))                         &kp LC(LA(LG(X))) &kp LC(LA(LG(U))) &dori_up &kp LC(LA(LG(O))) &kp LA(LG(N1)) &kp LC(LA(B))
               // ├──────────────┼──────────────┼──────────────┼──────────────┼──────────────┼──────────────┤                              ├──────────────┼──────────────┼──────────────┼──────────────┼──────────────┼──────────────┤
               // │ UNLOCK/AERO  │ Align Dyn.   │ Unison       │ Divisi       │ Filt Notes   │              │                              │ X Notehead   │ Decr Grid    │ Move/Cpy Dwn │ Incr Grid    │ Galley View  │ Res. Stems   │
                    &as_l AERO M_DORI_L &kp LS(LA(LG(A))) &kp LS(LC(D)) &kp LS(LG(D)) &kp LC(LA(LG(N))) &none                                &kp LS(LA(LG(X))) &kp LC(LA(LG(LEFT))) &dori_dn &kp LC(LA(LG(RIGHT))) &kp LA(LG(N2)) &kp LS(LA(LG(S)))
               // ├──────────────┼──────────────┼──────────────┼──────────────┼──────────────┼──────────────┼──────────────┐┌──────────────┼──────────────┼──────────────┼──────────────┼──────────────┼──────────────┼──────────────┤
               // │ SHIFT LEFT   │ Rem.Dyn.f.G. │ Ungroup Dyn. │ Group Dyn.   │ Filt&Rm Dyn. │ Dbl. Barline │              ││              │              │              │ Select More  │              │              │              │
                    &kp LSHFT      &kp LC(LG(G))  &kp LC(LA(LG(G))) &kp LC(LA(G)) &m_d_frd     &m_d_dbar      &none           &none          &none          &none          &kp LS(LG(A))  &none          &none          &none
               // └──────────────┴──────────────┼──────────────┼──────────────┼──────────────┼──────────────┼──────────────┤├──────────────┼──────────────┼──────────────┼──────────────┼──────────────┼──────────────┴──────────────┘
               //                               │              │              │              │              │              ││              │              │              │              │              │
                                                  &none          &none          &none          &to S_DORI     &none           &none          &to S_DORI     &none          &none          &none
               //                               └──────────────┴──────────────┴──────────────┴──────────────┴──────────────┘└──────────────┴──────────────┴──────────────┴──────────────┴──────────────┘
               >;
          };

          macros_coding_layer {
               display-name = "CODING";
               bindings = <
               // ┌──────────────┬──────────────┬──────────────┬──────────────┬──────────────┬──────────────┐                              ┌──────────────┬──────────────┬──────────────┬──────────────┬──────────────┬──────────────┐
               // │              │              │              │              │              │              │                              │              │              │              │              │              │              │
                    &none          &none          &none          &none          &none          &none                                         &none          &none          &none          &none          &none          &none
               // ├──────────────┼──────────────┼──────────────┼──────────────┼──────────────┼──────────────┤                              ├──────────────┼──────────────┼──────────────┼──────────────┼──────────────┼──────────────┤
               // │              │              │              │              │              │ VSC Terminal │                              │ <?php        │ /**          │ /* */        │ var_dump     │ console.log  │              │
                    &none          &none          &none          &none          &none          &kp LG(J)                                     &m_c_php       &m_c_docb      &m_c_bcom      &m_c_vdmp      &m_c_clog      &none
               // ├──────────────┼──────────────┼──────────────┼──────────────┼──────────────┼──────────────┤                              ├──────────────┼──────────────┼──────────────┼──────────────┼──────────────┼──────────────┤
               // │ LOCK/AERO    │ (() => {})   │              │              │ VSC Format   │ VSC Search   │                              │ $this->      │ ->           │ =>           │ ===          │ !==          │              │
                    &as_l AERO M_CODE_L &m_c_afnc &none          &none          &kp LS(LA(F))  &kp LS(LG(F))                                 &m_c_this      &m_c_tarr      &m_c_farr      &m_c_seq       &m_c_sneq      &none
               // ├──────────────┼──────────────┼──────────────┼──────────────┼──────────────┼──────────────┼──────────────┐┌──────────────┼──────────────┼──────────────┼──────────────┼──────────────┼──────────────┼──────────────┤
               // │              │              │              │              │              │              │              ││              │ <?=          │ END + ;      │ END + ; + RET│ !important   │              │              │
                    &none          &none          &none          &none          &none          &none          &none           &none          &m_c_php_e     &m_c_end       &m_c_endn      &m_c_imp       &none          &none
               // └──────────────┴──────────────┼──────────────┼──────────────┼──────────────┼──────────────┼──────────────┤├──────────────┼──────────────┼──────────────┼──────────────┼──────────────┼──────────────┴──────────────┘
               //                               │              │              │              │              │              ││              │              │              │              │              │
                                                  &none          &none          &none          &to S_CODE     &none           &none          &to S_CODE     &none          &none          &none
               //                               └──────────────┴──────────────┴──────────────┴──────────────┴──────────────┘└──────────────┴──────────────┴──────────────┴──────────────┴──────────────┘
               >;
          };

          macros_coding_locked_layer {
               display-name = "CODING";
               bindings = <
               // ┌──────────────┬──────────────┬──────────────┬──────────────┬──────────────┬──────────────┐                              ┌──────────────┬──────────────┬──────────────┬──────────────┬──────────────┬──────────────┐
               // │              │              │              │              │              │              │                              │              │              │              │              │              │              │
                    &none          &none          &none          &none          &none          &none                                         &none          &none          &none          &none          &none          &none
               // ├──────────────┼──────────────┼──────────────┼──────────────┼──────────────┼──────────────┤                              ├──────────────┼──────────────┼──────────────┼──────────────┼──────────────┼──────────────┤
               // │              │              │              │              │              │ VSC Terminal │                              │ <?php        │ /**          │ /* */        │ var_dump     │ console.log  │              │
                    &none          &none          &none          &none          &none          &kp LG(J)                                     &m_c_php       &m_c_docb      &m_c_bcom      &m_c_vdmp      &m_c_clog      &none
               // ├──────────────┼──────────────┼──────────────┼──────────────┼──────────────┼──────────────┤                              ├──────────────┼──────────────┼──────────────┼──────────────┼──────────────┼──────────────┤
               // │ LOCK/AERO    │ (() => {})   │              │              │ VSC Format   │ VSC Search   │                              │ $this->      │ ->           │ =>           │ ===          │ !==          │              │
                    &as_l AERO M_CODE_L &m_c_afnc &none          &none          &kp LS(LA(F))  &kp LS(LG(F))                                 &m_c_this      &m_c_tarr      &m_c_farr      &m_c_seq       &m_c_sneq      &none
               // ├──────────────┼──────────────┼──────────────┼──────────────┼──────────────┼──────────────┼──────────────┐┌──────────────┼──────────────┼──────────────┼──────────────┼──────────────┼──────────────┼──────────────┤
               // │              │              │              │              │              │              │              ││              │ <?=          │ END + ;      │ END + ; + RET│ !important   │              │              │
                    &none          &none          &none          &none          &none          &none          &none           &none          &m_c_php_e     &m_c_end       &m_c_endn      &m_c_imp       &none          &none
               // └──────────────┴──────────────┼──────────────┼──────────────┼──────────────┼──────────────┼──────────────┤├──────────────┼──────────────┼──────────────┼──────────────┼──────────────┼──────────────┴──────────────┘
               //                               │              │              │              │              │              ││              │              │              │              │              │
                                                  &none          &none          &none          &to S_CODE     &none           &none          &to S_CODE     &none          &none          &none
               //                               └──────────────┴──────────────┴──────────────┴──────────────┴──────────────┘└──────────────┴──────────────┴──────────────┴──────────────┴──────────────┘
               >;
          };

          aero_layer {
               display-name = "AERO";
               bindings = <
               // ┌──────────────┬──────────────┬──────────────┬──────────────┬──────────────┬──────────────┐                              ┌──────────────┬──────────────┬──────────────┬──────────────┬──────────────┬──────────────┐
               // │              │ Workspace 1  │ Workspace 2  │ Workspace 3  │ Workspace 4  │ Workspace 5  │                              │ Workspace 6  │ Workspace 7  │ Workspace 8  │ Workspace 9  │ Workspace 10 │              │
                    &trans         &kp LA(LC(N1)) &kp LA(LC(N2)) &kp LA(LC(N3)) &kp LA(LC(N4)) &kp LA(LC(N5))                                &kp LA(LC(N6)) &kp LA(LC(N7)) &kp LA(LC(N8)) &kp LA(LC(N9)) &kp LA(LC(N0)) &none
               // ├──────────────┼──────────────┼──────────────┼──────────────┼──────────────┼──────────────┤                              ├──────────────┼──────────────┼──────────────┼──────────────┼──────────────┼──────────────┤
               // │ TOGGLE WSPACE│ TOGGLE WSPACE│ PREV WSPACE  │ NEXT WSPACE  │ AERO RESIZE  │              │                              │              │ SHIFT LEFT   │ ↑            │              │              │              │
                    &kp LA(LC(TAB)) &kp LA(LC(TAB)) &kp LA(LC(W)) &kp LA(LC(E)) &mo AERO_R     &none                                         &none          &kp LSHFT      &kp LA(LC(UP)) &none          &none          &none
               // ├──────────────┼──────────────┼──────────────┼──────────────┼──────────────┼──────────────┤                              ├──────────────┼──────────────┼──────────────┼──────────────┼──────────────┼──────────────┤
               // │ (HELD)       │ LOCK         │ SHIFT LEFT   │ CMD LEFT     │ FULLSCREEN   │              │                              │ CMD LEFT     │ ←            │ ↓            │ →            │ Menu         │              │
                    &trans         &tog AERO_L    &kp LSHFT      &kp LGUI       &kp LA(LC(F))  &none                                         &kp LGUI     &kp LA(LC(LEFT)) &kp LA(LC(DOWN)) &kp LA(LC(RIGHT)) &kp LA(LC(SEMI))    &none
               // ├──────────────┼──────────────┼──────────────┼──────────────┼──────────────┼──────────────┼──────────────┐┌──────────────┼──────────────┼──────────────┼──────────────┼──────────────┼──────────────┼──────────────┤
               // │              │              │              │              │ FLOATING/TILING             │              ││              │ Workspace 1  │ Workspace 2  │ Workspace 3  │ Workspace 4  │ Workspace 5  │              │
                    &none          &none          &none          &none          &kp LS(LA(LC(F)))     &none   &none           &none          &kp LA(LC(N1)) &kp LA(LC(N2)) &kp LA(LC(N3)) &kp LA(LC(N4)) &kp LA(LC(N5)) &none
               // └──────────────┴──────────────┼──────────────┼──────────────┼──────────────┼──────────────┼──────────────┤├──────────────┼──────────────┼──────────────┼──────────────┼──────────────┼──────────────┴──────────────┘
               //                               │              │              │              │              │ LAUNCH MODE  ││ ALFRED       │              │              │              │              │
                                                  &none          &none          &none          &none   &kp LS(LA(LC(SPACE)))  &kp LA(LC(SPACE))     &none   &none          &none          &none
               //                               └──────────────┴──────────────┴──────────────┴──────────────┴──────────────┘└──────────────┴──────────────┴──────────────┴──────────────┴──────────────┘
               >;
          };

          aero_locked_layer {
               display-name = "AERO";
               bindings = <
               // ┌──────────────┬──────────────┬──────────────┬──────────────┬──────────────┬──────────────┐                              ┌──────────────┬──────────────┬──────────────┬──────────────┬──────────────┬──────────────┐
               // │              │ Workspace 1  │ Workspace 2  │ Workspace 3  │ Workspace 4  │ Workspace 5  │                              │ Workspace 6  │ Workspace 7  │ Workspace 8  │ Workspace 9  │ Workspace 10 │              │
                    &trans         &kp LA(LC(N1)) &kp LA(LC(N2)) &kp LA(LC(N3)) &kp LA(LC(N4)) &kp LA(LC(N5))                                &kp LA(LC(N6)) &kp LA(LC(N7)) &kp LA(LC(N8)) &kp LA(LC(N9)) &kp LA(LC(N0)) &none
               // ├──────────────┼──────────────┼──────────────┼──────────────┼──────────────┼──────────────┤                              ├──────────────┼──────────────┼──────────────┼──────────────┼──────────────┼──────────────┤
               // │ TOGGLE WSPACE│ TOGGLE WSPACE│ PREV WSPACE  │ NEXT WSPACE  │ AERO RESIZE  │              │                              │              │ SHIFT LEFT   │ ↑            │              │              │              │
                    &kp LA(LC(TAB)) &kp LA(LC(TAB)) &kp LA(LC(W)) &kp LA(LC(E)) &mo AERO_R     &none                                         &none          &kp LSHFT      &kp LA(LC(UP)) &none          &none          &none
               // ├──────────────┼──────────────┼──────────────┼──────────────┼──────────────┼──────────────┤                              ├──────────────┼──────────────┼──────────────┼──────────────┼──────────────┼──────────────┤
               // │ UNLOCK       │ UNLOCK       │ SHIFT LEFT   │ CMD LEFT     │ FULLSCREEN   │              │                              │ CMD LEFT     │ ←            │ ↓            │ →            │ Menu         │              │
                    &tog AERO_L    &tog AERO_L    &kp LSHFT      &kp LGUI       &kp LA(LC(F))  &none                                         &kp LGUI     &kp LA(LC(LEFT)) &kp LA(LC(DOWN)) &kp LA(LC(RIGHT)) &kp LA(LC(SEMI))    &none
               // ├──────────────┼──────────────┼──────────────┼──────────────┼──────────────┼──────────────┼──────────────┐┌──────────────┼──────────────┼──────────────┼──────────────┼──────────────┼──────────────┼──────────────┤
               // │              │              │              │              │ FLOATING/TILING             │              ││              │ Workspace 1  │ Workspace 2  │ Workspace 3  │ Workspace 4  │ Workspace 5  │              │
                    &none          &none          &none          &none          &kp LS(LA(LC(F)))     &none   &none           &none          &kp LA(LC(N1)) &kp LA(LC(N2)) &kp LA(LC(N3)) &kp LA(LC(N4)) &kp LA(LC(N5)) &none
               // └──────────────┴──────────────┼──────────────┼──────────────┼──────────────┼──────────────┼──────────────┤├──────────────┼──────────────┼──────────────┼──────────────┼──────────────┼──────────────┴──────────────┘
               //                               │              │              │              │              │ LAUNCH MODE  ││ ALFRED       │              │              │              │              │
                                                  &none          &none          &none          &none   &kp LS(LA(LC(SPACE)))  &kp LA(LC(SPACE))     &none   &none          &none          &none
               //                               └──────────────┴──────────────┴──────────────┴──────────────┴──────────────┘└──────────────┴──────────────┴──────────────┴──────────────┴──────────────┘
               >;
          };

          aero_resize_layer {
               display-name = "RESIZE";
               bindings = <
               // ┌──────────────┬──────────────┬──────────────┬──────────────┬──────────────┬──────────────┐                              ┌──────────────┬──────────────┬──────────────┬──────────────┬──────────────┬──────────────┐
               // │              │              │              │              │              │              │                              │              │              │              │              │              │              │
                    &trans         &none          &none          &none          &none          &none                                         &none          &none          &none          &none          &none          &none
               // ├──────────────┼──────────────┼──────────────┼──────────────┼──────────────┼──────────────┤                              ├──────────────┼──────────────┼──────────────┼──────────────┼──────────────┼──────────────┤
               // │              │              │              │ BIG RESIZE   │ (HELD)       │              │                              │                BALANCE SIZE │ ↑            │ FLATTEN TREE │              │              │
                    &none          &none          &none          &kp LSHFT      &trans         &none                                         &none        &kp LA(LC(F20))  &kp LA(LC(F18)) &kp LS(LA(LC(F20)))  &none   &none
               // ├──────────────┼──────────────┼──────────────┼──────────────┼──────────────┼──────────────┤                              ├──────────────┼──────────────┼──────────────┼──────────────┼──────────────┼──────────────┤
               // │ (HELD)       │              │              │              │              │              │                              │              │ ←            │ ↓            │ →            │              │              │
                    &trans         &none          &none          &none          &none          &none                                         &none        &kp LA(LC(F16)) &kp LA(LC(F19)) &kp LA(LC(F17))       &none   &none
               // ├──────────────┼──────────────┼──────────────┼──────────────┼──────────────┼──────────────┼──────────────┐┌──────────────┼──────────────┼──────────────┼──────────────┼──────────────┼──────────────┼──────────────┤
               // │              │              │              │              │              │              │              ││              │              │              │              │              │              │              │
                    &none          &none          &none          &none          &none          &none          &none           &none          &none          &none          &none          &none          &none          &none
               // └──────────────┴──────────────┼──────────────┼──────────────┼──────────────┼──────────────┼──────────────┤├──────────────┼──────────────┼──────────────┼──────────────┼──────────────┼──────────────┴──────────────┘
               //                               │              │              │              │              │              ││              │              │              │              │              │
                                                  &none          &none          &none          &none          &none           &none          &none          &none          &none          &none
               //                               └──────────────┴──────────────┴──────────────┴──────────────┴──────────────┘└──────────────┴──────────────┴──────────────┴──────────────┴──────────────┘
               >;
          };

          service_layer {
               display-name = "SERVICE";
               bindings = <
               // ┌──────────────┬──────────────┬──────────────┬──────────────┬──────────────┬──────────────┐                              ┌──────────────┬──────────────┬──────────────┬──────────────┬──────────────┬──────────────┐
               // │              │ BLUETOOTH 1  │ BLUETOOTH 2  │ BLUETOOTH 3  │ BLUETOOTH 4  │ BLUETOOTH 5  │                              │              │              │              │              │              │ BT CLEAR     │
                    &none          &bt BT_SEL 0   &bt BT_SEL 1   &bt BT_SEL 2   &bt BT_SEL 3   &bt BT_SEL 4                                  &none          &none          &none          &none          &none          &bt BT_CLR
               // ├──────────────┼──────────────┼──────────────┼──────────────┼──────────────┼──────────────┤                              ├──────────────┼──────────────┼──────────────┼──────────────┼──────────────┼──────────────┤
               // │              │              │              │              │              │              │                              │ RGB TOGGLE   │ BRI DOWN     │ BRI UP       │ ANIM PREV    │ ANIM NEXT    │              │
                    &none          &none          &none          &none          &none          &none                                        &rgb_ug RGB_TOG &rgb_ug RGB_BRD &rgb_ug RGB_BRI &rgb_ug RGB_EFR &rgb_ug RGB_EFF    &none
               // ├──────────────┼──────────────┼──────────────┼──────────────┼──────────────┼──────────────┤                              ├──────────────┼──────────────┼──────────────┼──────────────┼──────────────┼──────────────┤
               // │ (UN)LOCK     │              │              │              │              │              │                              │              │ HUE DOWN     │ HUE UP       │ SPEED DOWN   │ SPEED UP     │              │
                    &tog SERV      &none          &none          &none          &none          &none                                         &none         &rgb_ug RGB_HUD &rgb_ug RGB_HUI &rgb_ug RGB_SPD &rgb_ug RGB_SPI     &none
               // ├──────────────┼──────────────┼──────────────┼──────────────┼──────────────┼──────────────┼──────────────┐┌──────────────┼──────────────┼──────────────┼──────────────┼──────────────┼──────────────┼──────────────┤
               // │              │              │              │              │              │              │              ││ ZMK Studio Unlock           │ SAT DOWN     │ SAT UP       │              │              │              │
                    &none          &none          &none          &none          &none          &none          &none           &studio_unlock &none          &rgb_ug RGB_SAD &rgb_ug RGB_SAI &none        &none          &none
               // └──────────────┴──────────────┼──────────────┼──────────────┼──────────────┼──────────────┼──────────────┤├──────────────┼──────────────┼──────────────┼──────────────┼──────────────┼──────────────┴──────────────┘
               //                               │              │              │              │ (HELD)       │              ││              │ (HELD)       │              │              │              │
                                                  &none          &none          &none          &trans         &none           &none          &trans         &none          &none          &none
               //                               └──────────────┴──────────────┴──────────────┴──────────────┴──────────────┘└──────────────┴──────────────┴──────────────┴──────────────┴──────────────┘
               >;
          };
     };
};
